# DEBUGSS_1.0 register map
Vendor: Texas Instruments
Peripheral module from a debugger description file (folder mspm0l211x_l112x).
Registers are 32-bit, read-write, no defined reset value unless marked. A register's access mark holds for its fields unless they carry their own. Offsets are as the file gives them; lines under a group give offsets from that group; [hi:lo] are bit positions; {n}, {i} and the like mark numbered series; 'fields as' and 'values as' point back to an identical list; <NAME> marks a mode.

## DEBUGSS
0x1020 DEBUGSS_CPU_INT group
  0x00 DEBUGSS_IIDX — Interrupt index
    [7:0] STAT — Interrupt index status
      0=NO_INTR (No pending interrupt request); 1=TXIFG (TX interrupt); 2=RXIFG (RX interrupt); 3=PWRUP (Power-up interrupt. A debug session has started.); 4=PWRDWN (Power-up interrupt. A debug session has started.)
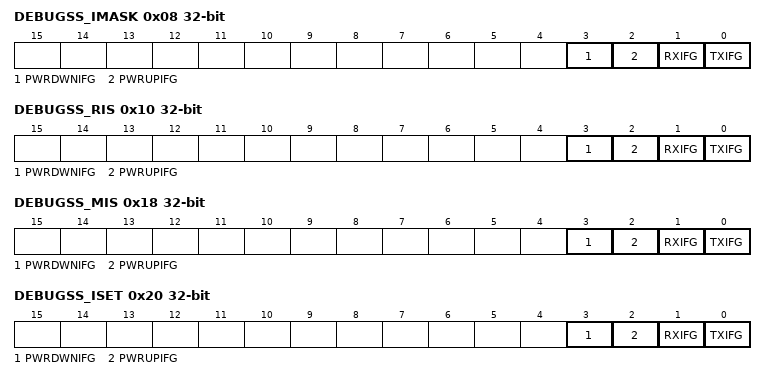
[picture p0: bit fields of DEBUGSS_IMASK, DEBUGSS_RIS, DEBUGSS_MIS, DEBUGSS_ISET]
  0x08 DEBUGSS_IMASK — Interrupt mask
    [all] fields
      0=CLR (Interrupt is masked out); 1=SET (Interrupt will request an interrupt service routine and corresponding bit in MIS will be set)
    [3] PWRDWNIFG — Masks PWRDWNIFG in MIS register
    [2] PWRUPIFG — Masks PWRUPIFG in MIS register
    [1] RXIFG — Masks RXIFG in MIS register
    [0] TXIFG — Masks TXIFG in MIS register
  0x10 DEBUGSS_RIS — Raw interrupt status
    [3] PWRDWNIFG — Raw interrupt status for PWRDWNIFG
      0=CLR (PWRUPIFG did not occur); 1=SET (PWRUPIFG occurred)
    [2] PWRUPIFG — Raw interrupt status for PWRUPIFG
      0=CLR (PWRUPIFG did not occur); 1=SET (PWRUPIFG occurred)
    [1] RXIFG — Raw interrupt status for RXIFG
      0=CLR (RXIFG did not occur); 1=SET (RXIFG occurred)
    [0] TXIFG — Raw interrupt status for TXIFG
      0=CLR (TXIFG did not occur); 1=SET (TXIFG occurred)
  0x18 DEBUGSS_MIS — Masked interrupt status
    [3] PWRDWNIFG — Masked interrupt status for PWRDWNIFG
      0=CLR (PWRUPIFG did not request an interrupt service routine); 1=SET (PWRUPIFG requests an interrupt service routine)
    [2] PWRUPIFG — Masked interrupt status for PWRUPIFG
      values as PWRDWNIFG
    [1] RXIFG — Masked interrupt status for RXIFG
      0=CLR (RXIFG did not request an interrupt service routine); 1=SET (RXIFG requests an interrupt service routine)
    [0] TXIFG — Masked interrupt status for TXIFG
      0=CLR (TXIFG did not request an interrupt service routine); 1=SET (TXIFG requests an interrupt service routine)
  0x20 DEBUGSS_ISET — Interrupt set
    [3] PWRDWNIFG — Sets PWRDWNIFG in RIS register
      0=NO_EFFECT (Writing a 0 has no effect); 1=SET (RIS bit corresponding to PWRUPIFG is set)
    [2] PWRUPIFG — Sets PWRUPIFG in RIS register
      values as PWRDWNIFG
    [1] RXIFG — Sets RXIFG in RIS register
      0=NO_EFFECT (Writing a 0 has no effect); 1=SET (RIS bit corresponding to RXIFG is set)
    [0] TXIFG — Sets TXIFG in RIS register
      0=NO_EFFECT (Writing a 0 has no effect); 1=SET (RIS bit corresponding to TXIFG is set)
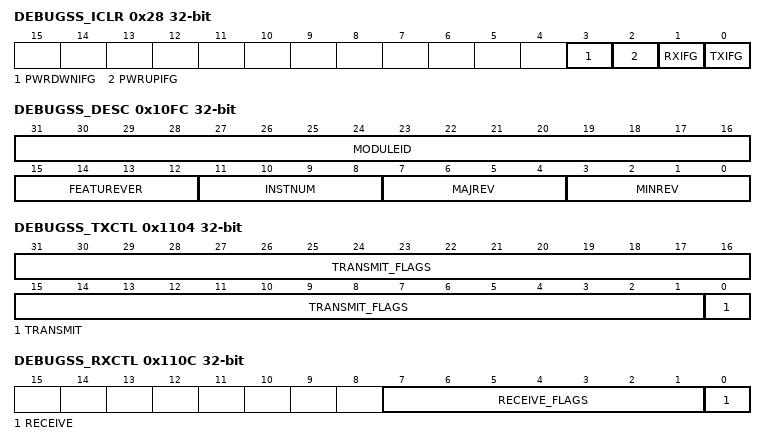
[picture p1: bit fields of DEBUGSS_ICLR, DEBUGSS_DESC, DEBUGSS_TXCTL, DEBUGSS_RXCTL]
  0x28 DEBUGSS_ICLR — Interrupt clear
    [3] PWRDWNIFG — Clears PWRDWNIFG in RIS register
      0=NO_EFFECT (Writing a 0 has no effect); 1=CLR (RIS bit corresponding to PWRUPIFG is cleared)
    [2] PWRUPIFG — Clears PWRUPIFG in RIS register
      values as PWRDWNIFG
    [1] RXIFG — Clears RXIFG in RIS register
      0=NO_EFFECT (Writing a 0 has no effect); 1=CLR (RIS bit corresponding to RXIFG is cleared)
    [0] TXIFG — Clears TXIFG in RIS register
      0=NO_EFFECT (Writing a 0 has no effect); 1=CLR (RIS bit corresponding to TXIFG is cleared)
0x10E0 DEBUGSS_EVT_MODE ro — Event Mode
  [1:0] INT0_CFG — Event line mode select for peripheral events
    0=DISABLE (The interrupt or event line is disabled.); 1=SOFTWARE (The interrupt or event line is in software mode. Software must clear the RIS.); 2=HARDWARE (The interrupt or event line is in hardware mode. The hardware (another module) clears automatically the associated RIS flag.)
0x10FC DEBUGSS_DESC — Module Description
  [31:16] MODULEID — Module identification contains a unique peripheral identification number. The assignments are maintained in a central database for all of the platform modules to ensure uniqueness.
  [15:12] FEATUREVER — Feature Set for the module *instance*
  [11:8] INSTNUM — Instance Number within the device. This will be a parameter to the RTL for modules that can have multiple instances
  [7:4] MAJREV — Major rev of the IP
  [3:0] MINREV — Minor rev of the IP
0x1100 DEBUGSS_TXD access not given — Transmit data register
0x1104 DEBUGSS_TXCTL ro — Transmit control register
  [31:1] TRANSMIT_FLAGS — Generic TX flags that can be set by external debug tool. Functionality is defined by SW.
  [0] TRANSMIT — Indicates data request in DSSM.TXD, set on write via Debug AP to DSSM.TXD. A read of the DSSM.TXD register by SW will clear the TX field. The tool can check that TXD is empty by reading this field.
    0=EMPTY (TXD is empty); 1=FULL (TXD is full)
0x1108 DEBUGSS_RXD access not given — Receive data register
0x110C DEBUGSS_RXCTL access per field — Receive control register
  [7:1] RECEIVE_FLAGS rw — Generic RX flags that can be set by SW and read by external debug tool. Functionality is defined by SW.
  [0] RECEIVE ro — Indicates SW write to the DSSM.RXD register. A read of the DSSM.RXD register by SWD Access Port will clear the RX field.
    0=EMPTY (RXD empty); 1=FULL (RXD full)
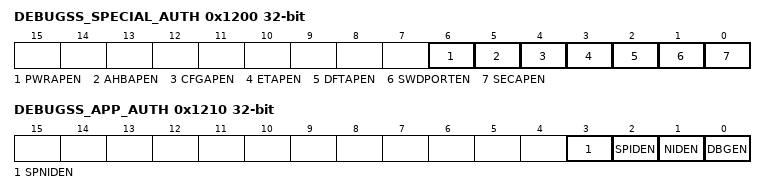
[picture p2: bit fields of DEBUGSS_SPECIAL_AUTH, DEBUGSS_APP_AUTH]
0x1200 DEBUGSS_SPECIAL_AUTH ro — Special enable authorization register
  [6] PWRAPEN — An active high input. When asserted (and SWD access is also permitted), the debug tools can then access the PWR-AP to power and reset state of the CPU. When deasserted, a DAPBUS firewall will isolate the AP and prevent access.
    0=DISABLE (Disable PWR-AP); 1=ENABLE (Enable PWR-AP)
  [5] AHBAPEN — Disabling / enabling debug access to the M0+ Core via the AHB-AP DAP bus isolation.
    0=DISABLE (Disable AHB-AP); 1=ENABLE (Enable AHB-AP)
  [4] CFGAPEN — An active high input. When asserted (and SWD access is also permitted), the debug tools can use the Config-AP to read device configuration information. When deasserted, a DAPBUS firewall will isolate the AP and prevent access to the Config-AP.
    0=DISABLE (Disable CFG-AP); 1=ENABLE (Enable CFG-AP)
  [3] ETAPEN — An active high input. When asserted (and SWD access is also permitted), the debug tools can then access an ET-AP external to the DebugSS lite. When deasserted, a DAPBUS firewall will isolate the AP and prevent access.
    0=DISABLE (Disable ET+ -AP); 1=ENABLE (Enable ET+ -AP)
  [2] DFTAPEN — An active high input. When asserted (and SWD access is also permitted), the debug tools can then access the DFT-AP external to the DebugSS lite. When deasserted, a DAPBUS firewall will isolate the AP and prevent access.
    0=DISABLE (Disable DFT-TAP); 1=ENABLE (Enable DFT-TAP)
  [1] SWDPORTEN — When asserted, the SW-DP functions normally. When deasserted, the SW-DP effectively disables all external debug access.
    0=DISABLE (Disable SWD port); 1=ENABLE (Enable SWD port)
  [0] SECAPEN — An active high input. When asserted (and SWD access is also permitted), the debug tools can use the Security-AP to communicate with security control logic. When deasserted, a DAPBUS firewall will isolate the AP and prevent access to the Security-AP.
    0=DISABLE (Disable SEC-AP); 1=ENABLE (Enable SEC-AP)
0x1210 DEBUGSS_APP_AUTH ro — Application CPU0 authorization register
  [3] SPNIDEN — Secure non-invasive debug enable.
    0=DISABLE (Invasive debug disabled); 1=ENABLE (Invasive debug enabled)
  [2] SPIDEN — Secure invasive debug enable.
    values as SPNIDEN
  [1] NIDEN — Controls non-invasive debug enable.
    0=DISABLE (Non-invasive debug disabled); 1=ENABLE (Non-invasive debug enabled)
  [0] DBGEN — Controls invasive debug enable.
    values as SPNIDEN
